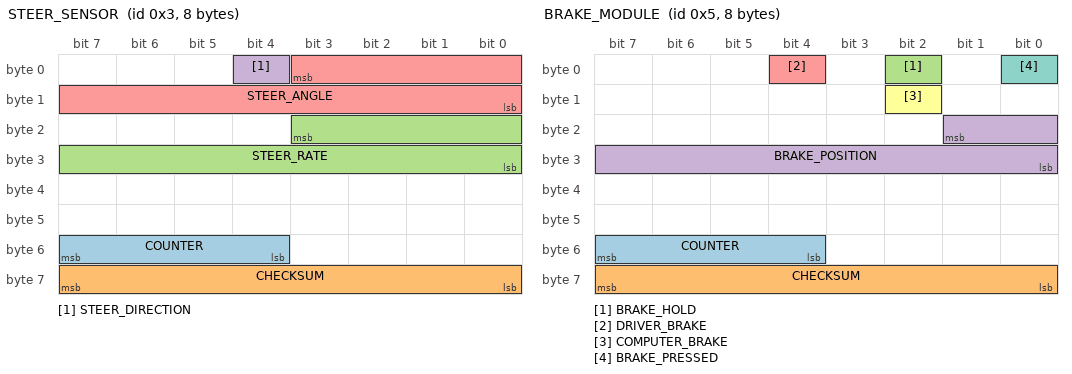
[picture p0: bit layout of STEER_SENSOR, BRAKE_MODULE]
BO_ 3 STEER_SENSOR: 8 XXX
 SG_ COUNTER : 55|4@0+ (1,0) [0|15] "" XXX
 SG_ CHECKSUM : 63|8@0+ (1,0) [0|255] "" XXX
 SG_ STEER_RATE : 19|12@0- (0.5,0) [0|255] "" XXX
 SG_ STEER_DIRECTION : 4|1@0+ (1,2) [0|1] "" XXX
 SG_ STEER_ANGLE : 3|12@0- (-0.5,0) [-500|500] "degrees" XXX

BO_ 5 BRAKE_MODULE: 8 XXX
 SG_ COUNTER : 55|4@0+ (1,0) [0|15] "" XXX
 SG_ CHECKSUM : 63|8@0+ (1,0) [0|255] "" XXX
 SG_ BRAKE_HOLD : 2|1@0+ (1,0) [0|1] "" XXX
 SG_ BRAKE_POSITION : 17|10@0+ (1,0) [0|65535] "" XXX
 SG_ DRIVER_BRAKE : 4|1@0+ (1,0) [0|1] "" XXX
 SG_ COMPUTER_BRAKE : 10|1@0+ (1,0) [0|1] "" XXX
 SG_ BRAKE_PRESSED : 0|1@1+ (1,0) [0|1] "" XXX

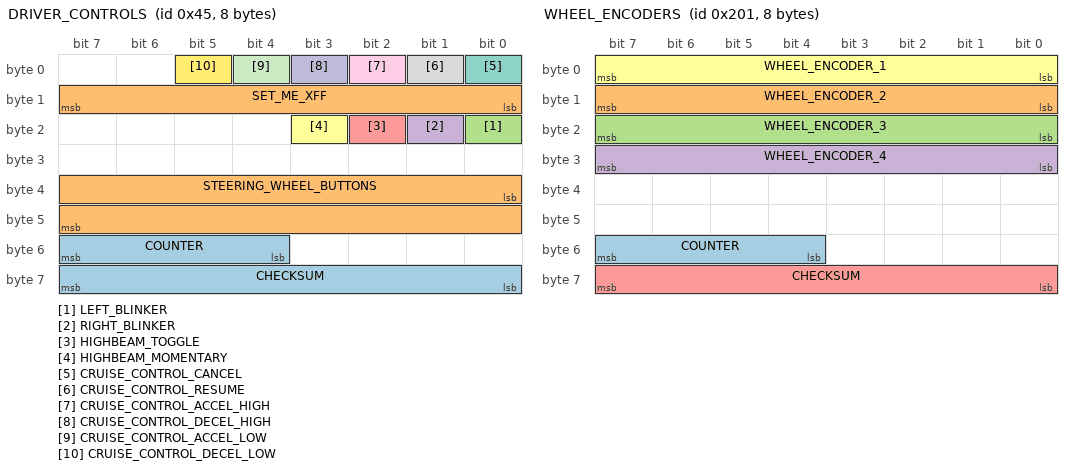
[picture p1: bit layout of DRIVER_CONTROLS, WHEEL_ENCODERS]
BO_ 69 DRIVER_CONTROLS: 8 XXX
 SG_ COUNTER : 55|4@0+ (1,0) [0|15] "" XXX
 SG_ STEERING_WHEEL_BUTTONS : 32|16@1+ (1,0) [0|255] "4 directional, 2 volume control & 2 phone buttons" XXX
 SG_ LEFT_BLINKER : 16|1@0+ (1,0) [0|1] "" XXX
 SG_ RIGHT_BLINKER : 17|1@0+ (1,0) [0|1] "" XXX
 SG_ HIGHBEAM_TOGGLE : 18|1@0+ (1,0) [0|1] "" XXX
 SG_ HIGHBEAM_MOMENTARY : 19|1@0+ (1,0) [0|1] "" XXX
 SG_ CRUISE_CONTROL_CANCEL : 0|1@0+ (1,0) [0|1] "" XXX
 SG_ CRUISE_CONTROL_RESUME : 1|1@0+ (1,0) [0|1] "" XXX
 SG_ CRUISE_CONTROL_ACCEL_HIGH : 2|1@0+ (1,0) [0|1] "" XXX
 SG_ CRUISE_CONTROL_DECEL_HIGH : 3|1@0+ (1,0) [0|1] "" XXX
 SG_ CRUISE_CONTROL_ACCEL_LOW : 4|1@0+ (1,0) [0|1] "" XXX
 SG_ CRUISE_CONTROL_DECEL_LOW : 5|1@0+ (1,0) [0|1] "" XXX
 SG_ CHECKSUM : 63|8@0+ (1,0) [0|255] "" XXX
 SG_ SET_ME_XFF : 15|8@0+ (1,0) [0|255] "" XXX

BO_ 513 WHEEL_ENCODERS: 8 XXX
 SG_ COUNTER : 55|4@0+ (1,0) [0|15] "" XXX
 SG_ WHEEL_ENCODER_2 : 15|8@0+ (1,0) [0|255] "" XXX
 SG_ WHEEL_ENCODER_3 : 23|8@0+ (1,0) [0|255] "" XXX
 SG_ WHEEL_ENCODER_4 : 31|8@0+ (1,0) [0|255] "" XXX
 SG_ CHECKSUM : 56|8@1+ (1,0) [0|255] "" XXX
 SG_ WHEEL_ENCODER_1 : 7|8@0+ (1,0) [0|255] "" XXX

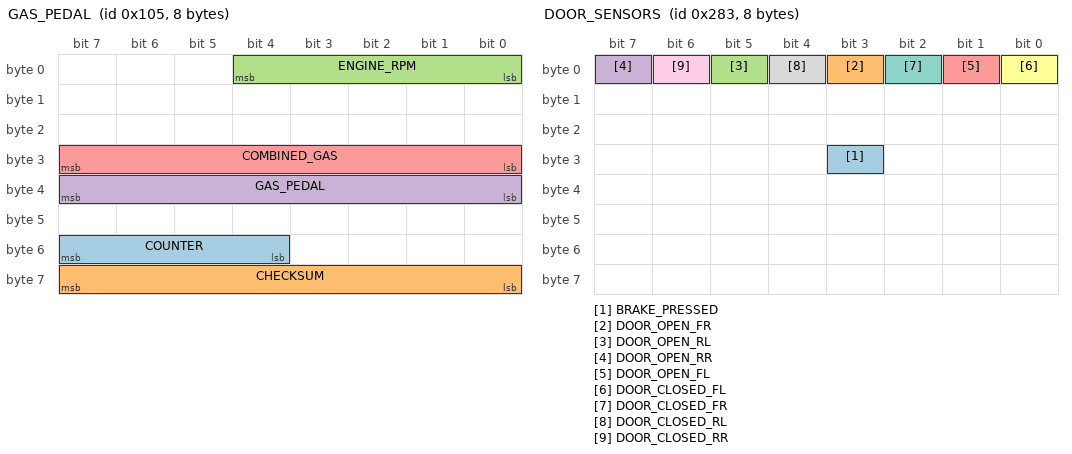
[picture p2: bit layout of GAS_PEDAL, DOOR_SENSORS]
BO_ 261 GAS_PEDAL: 8 XXX
 SG_ COUNTER : 55|4@0+ (1,0) [0|15] "" XXX
 SG_ CHECKSUM : 63|8@0+ (1,0) [0|255] "" XXX
 SG_ ENGINE_RPM : 4|5@0+ (1,0) [0|255] "" XXX
 SG_ GAS_PEDAL : 39|8@0+ (1,0) [0|255] "" XXX
 SG_ COMBINED_GAS : 31|8@0+ (1,0) [0|255] "" XXX

BO_ 643 DOOR_SENSORS: 8 XXX
 SG_ BRAKE_PRESSED : 27|1@0+ (1,0) [0|1] "" XXX
 SG_ DOOR_OPEN_FR : 3|1@1+ (1,0) [0|3] "" XXX
 SG_ DOOR_OPEN_RL : 5|1@0+ (1,0) [0|3] "" XXX
 SG_ DOOR_OPEN_RR : 7|1@0+ (1,0) [0|3] "" XXX
 SG_ DOOR_OPEN_FL : 1|1@0+ (1,0) [0|1] "" XXX
 SG_ DOOR_CLOSED_FL : 0|1@0+ (1,0) [0|1] "" XXX
 SG_ DOOR_CLOSED_FR : 2|1@0+ (1,0) [0|1] "" XXX
 SG_ DOOR_CLOSED_RL : 4|1@0+ (1,0) [0|1] "" XXX
 SG_ DOOR_CLOSED_RR : 6|1@0+ (1,0) [0|1] "" XXX

BO_ 885 SEATBELT_SENSORS: 8 XXX
 SG_ SEATBELT_DRIVER_LATCHED : 16|1@0+ (1,0) [0|1] "" XXX
 SG_ SEATBELT_PASSENGER_LATCHED : 18|1@0+ (1,0) [0|1] "" XXX

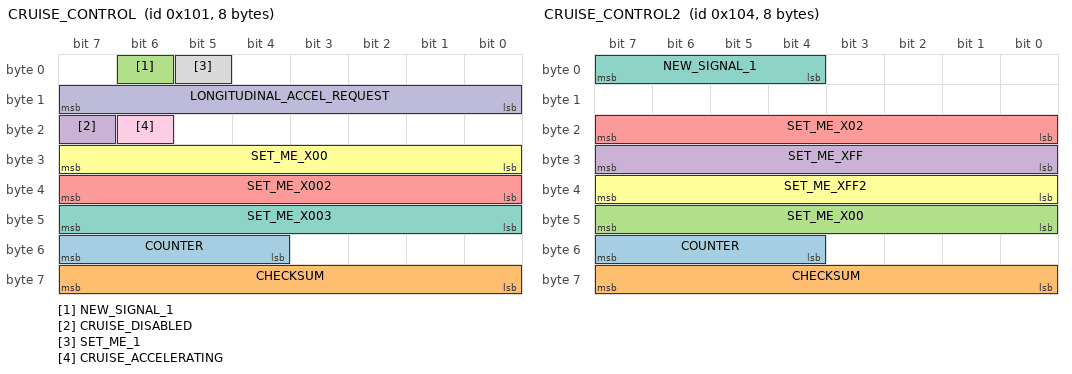
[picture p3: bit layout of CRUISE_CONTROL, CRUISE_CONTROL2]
BO_ 257 CRUISE_CONTROL: 8 XXX
 SG_ COUNTER : 55|4@0+ (1,0) [0|15] "" XXX
 SG_ CHECKSUM : 63|8@0+ (1,0) [0|255] "" XXX
 SG_ NEW_SIGNAL_1 : 6|1@0+ (1,0) [0|255] "" XXX
 SG_ CRUISE_DISABLED : 23|1@0+ (1,0) [0|1] "" XXX
 SG_ SET_ME_X002 : 39|8@0+ (1,0) [0|255] "" XXX
 SG_ SET_ME_X00 : 31|8@0+ (1,0) [0|255] "" XXX
 SG_ SET_ME_X003 : 47|8@0+ (1,0) [0|255] "" XXX
 SG_ SET_ME_1 : 5|1@0+ (1,0) [0|1] "" XXX
 SG_ CRUISE_ACCELERATING : 22|1@0+ (1,0) [0|1] "" XXX
 SG_ LONGITUDINAL_ACCEL_REQUEST : 15|8@0- (1,0) [0|127] "" XXX

BO_ 260 CRUISE_CONTROL2: 8 XXX
 SG_ COUNTER : 55|4@0+ (1,0) [0|15] "" XXX
 SG_ CHECKSUM : 63|8@0+ (1,0) [0|255] "" XXX
 SG_ SET_ME_X00 : 47|8@0+ (1,0) [0|255] "" XXX
 SG_ SET_ME_XFF : 31|8@0+ (1,0) [0|65535] "" XXX
 SG_ SET_ME_X02 : 23|8@0+ (1,0) [0|255] "" XXX
 SG_ SET_ME_XFF2 : 39|8@0+ (1,0) [0|255] "" XXX
 SG_ NEW_SIGNAL_1 : 7|4@0+ (1,0) [0|255] "" XXX

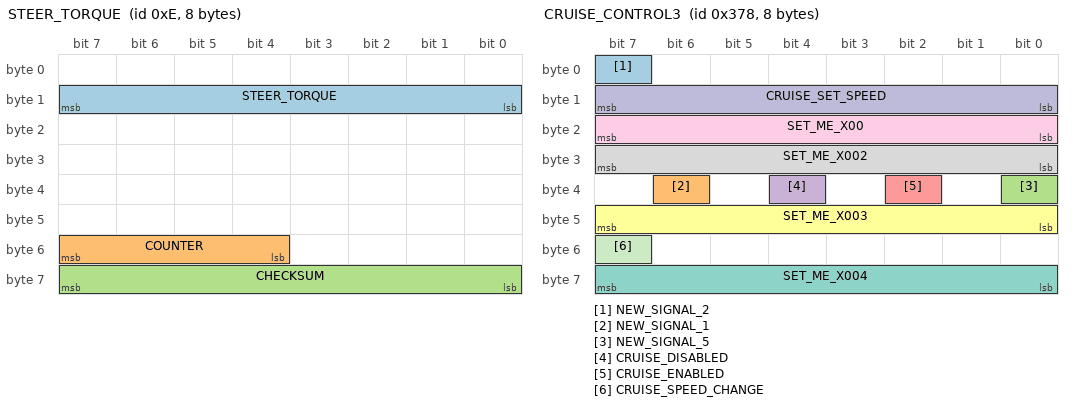
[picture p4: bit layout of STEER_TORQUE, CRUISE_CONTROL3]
BO_ 14 STEER_TORQUE: 8 XXX
 SG_ STEER_TORQUE : 15|8@0+ (1,0) [0|255] "" XXX
 SG_ COUNTER : 55|4@0+ (1,0) [0|15] "" XXX
 SG_ CHECKSUM : 63|8@0+ (1,0) [0|255] "" XXX

BO_ 888 CRUISE_CONTROL3: 8 XXX
 SG_ NEW_SIGNAL_2 : 7|1@0+ (1,0) [0|1] "" XXX
 SG_ NEW_SIGNAL_1 : 38|1@0+ (1,0) [0|1] "" XXX
 SG_ NEW_SIGNAL_5 : 32|1@0+ (1,0) [0|1] "" XXX
 SG_ CRUISE_DISABLED : 36|1@0+ (1,0) [0|1] "" XXX
 SG_ CRUISE_ENABLED : 34|1@0+ (1,0) [0|1] "" XXX
 SG_ SET_ME_X003 : 47|8@0+ (1,0) [0|255] "" XXX
 SG_ SET_ME_X004 : 63|8@0+ (1,0) [0|255] "" XXX
 SG_ SET_ME_X002 : 31|8@0+ (1,0) [0|255] "" XXX
 SG_ SET_ME_X00 : 23|8@0+ (1,0) [0|255] "" XXX
 SG_ CRUISE_SET_SPEED : 15|8@0+ (1,0) [0|63] "mph" XXX
 SG_ CRUISE_SPEED_CHANGE : 55|1@0+ (1,0) [0|1] "" XXX

BO_ 307 POWER_SEATS: 8 XXX
 SG_ DRIVER_FORWARD : 0|1@0+ (1,0) [0|1] "" XXX
 SG_ DRIVER_BACK : 1|1@0+ (1,0) [0|1] "" XXX

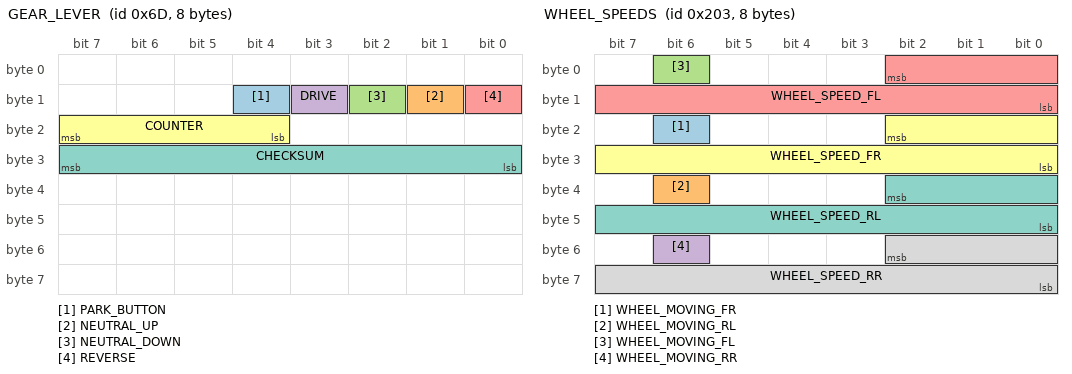
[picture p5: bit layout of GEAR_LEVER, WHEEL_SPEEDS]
BO_ 109 GEAR_LEVER: 8 XXX
 SG_ PARK_BUTTON : 12|1@0+ (1,0) [0|1] "" XXX
 SG_ NEUTRAL_UP : 9|1@0+ (1,0) [0|1] "" XXX
 SG_ NEUTRAL_DOWN : 10|1@0+ (1,0) [0|1] "" XXX
 SG_ DRIVE : 11|1@0+ (1,0) [0|1] "" XXX
 SG_ REVERSE : 8|1@0+ (1,0) [0|1] "" XXX
 SG_ COUNTER : 23|4@0+ (1,0) [0|15] "" XXX
 SG_ CHECKSUM : 31|8@0+ (1,0) [0|255] "" XXX

BO_ 115 GEAR_PACKET: 8 XXX
 SG_ GEAR : 0|4@1+ (1,0) [0|15] "" XXX

BO_ 581 IGNITION: 8 XXX

BO_ 515 WHEEL_SPEEDS: 8 XXX
 SG_ WHEEL_MOVING_FR : 22|1@1+ (1,0) [0|15] "" XXX
 SG_ WHEEL_MOVING_RL : 38|1@0+ (1,0) [0|1] "" XXX
 SG_ WHEEL_MOVING_FL : 6|1@0+ (1,0) [0|1] "" XXX
 SG_ WHEEL_MOVING_RR : 54|1@0+ (1,0) [0|1] "" XXX
 SG_ WHEEL_SPEED_FL : 2|11@0+ (0.0375,0) [0|255] "mph" XXX
 SG_ WHEEL_SPEED_FR : 18|11@0+ (0.0375,0) [0|255] "mph" XXX
 SG_ WHEEL_SPEED_RL : 34|11@0+ (0.0375,0) [0|255] "mph" XXX
 SG_ WHEEL_SPEED_RR : 50|11@0+ (0.0375,0) [0|255] "mph" XXX

BU_: K182_PACM K43_PSCM K17_EBCM NEO K124_ASCM

CM_ "AUTOGENERATED FILE, DO NOT EDIT";

CM_ "Imported file _subaru_global.dbc starts here";
CM_ SG_ 64 Throttle_Combo "Throttle Cruise + Pedal";
CM_ SG_ 313 Brake_Lights "Driver or Cruise Brake on";
CM_ SG_ 544 Cruise_Brake_Lights "1 = switch on brake lights";
CM_ SG_ 544 Brake_Pressure "Winds down after cruise disabled. Also can be non-zero when likely preparing for AEB";
CM_ SG_ 544 Signal3 "Usually goes to 2 if AEB_Status is 4";
CM_ SG_ 544 AEB_Status "Occasionally is 4 instead of 8 while Brake_Pressure is non-zero, unsure why";
CM_ SG_ 801 PCB_Off "Pre-Collision Braking off";
CM_ SG_ 801 Brake_Lights "Driver or Cruise brake on";
CM_ SG_ 801 Cruise_State "0 = Normal, 1 = Hold+User Brake, 2 = Ready, 3 = Hold";
CM_ SG_ 801 Far_Distance "1=0-5m, 2=5-10m, 3=10-15m, 4=15-20m, 5=20-25m, 6=25-30m, 7=30-35m, 8=35-40m, 9=40-45m, 10=45-50m, 11=50-55m, 12=55-60m, 13=60-65m, 14=65-70m, 15=75m+";
CM_ SG_ 801 LKAS_State_Msg "1 = LKAS_Off_Sharp_Curve, 2 = Keep_Hands_On_Steering_wheel_disabled, 3 = LKAS_Off, 4 = LKAS_Off_Too_Slow, 5 = LKAS_Off_Too_Fast";
CM_ SG_ 801 Cruise_State_Msg "1 = Cruise_Off_Steep_Slope, 2 = Cruise_lvl1_eco, 3 = Cruise_lvl2_comfort, 4 = Cruise_off_empty_reason, 5 = Cruise_off, 6 = Cruise_Unable_to_set, 7 = Cruise_Unable_to_set_brakes_applied, 8 = Eyesight_not_ready, 9 = Cruise_lvl3_standard, 10 = Cruise_lvl4_dynamic, 11 = Cruise_Unable_to_set_steep_slope";
CM_ SG_ 801 Cruise_Soft_Disable "Eyesight soft disable (eg direct sunlight)";
CM_ SG_ 801 Cruise_Status_Msg "1 = Disabled_Bad_Visibility, 2 = Disabled_Check_Manual";
CM_ SG_ 802 LKAS_ACTIVE "Turns on the full LKAS dash display";
CM_ SG_ 802 LKAS_Alert_Msg "1 = Keep_Hands_On_Wheel, 6 = Pre_Collision_Braking, 7 = Keep_Hands_On_Wheel_Off";
CM_ SG_ 802 LKAS_Alert "1 = FCW_Cont_Beep, 2 = FCW_Repeated_Beep, 3 = Throttle_Management_Activated_Warning, 4 = Throttle_Management_Activated_Alert, 5 = Pre_Collision_Activated_Alert, 8 = Traffic_Light_Ahead, 9 = Apply_Brake_to_Hold Position, 11 = LDW_Right, 12 = LDW_Left, 13 = Stay_Alert, 14 = Lead_Vehicle_Start_Alert, 18 = Keep_Hands_On_Steering_Alert, 24 = Audio_Beep, 25 = Audio_Lead_Car_Change, 26 = Audio_ACC_Disengaged, 27 = Audio_LKAS_disabled, 28 = Audio_Ding_Ding, 30 = Audio_Repeated_Beep";
CM_ SG_ 802 LKAS_Left_Line_Visible "0 = Off, 1 = White, 2 = Green, 3 = Orange";
CM_ SG_ 802 LKAS_Dash_State "0 = Off, 1 = Ready, 2 = Active";
CM_ SG_ 802 LKAS_Right_Line_Visible "0 = Off, 1 = White, 2 = Green, 3 = Orange";
CM_ SG_ 912 UNITS "0 = Metric, 1 = Imperial";
CM_ SG_ 912 ICY_ROAD "1 = DASHLIGHT ON, 2 = WARNING, 3 = OFF";
CM_ "subaru_global_2020_hybrid.dbc starts here";
